VERSION "0.6.1"

NS_ :

BS_:

BU_:

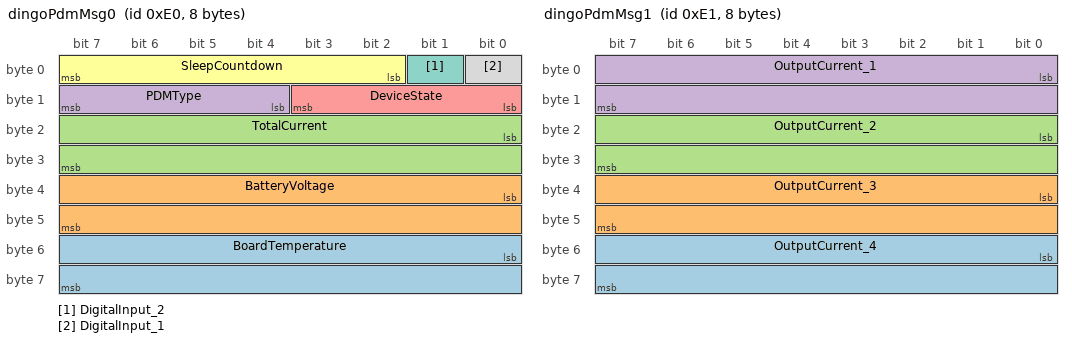
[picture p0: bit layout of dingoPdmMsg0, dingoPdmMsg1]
BO_ 224 dingoPdmMsg0: 8 Vector__XXX
 SG_ BoardTemperature : 48|16@1+ (0.1,0) [0|215] "degC" Vector__XXX
 SG_ BatteryVoltage : 32|16@1+ (0.1,0) [0|655.35] "V" Vector__XXX
 SG_ TotalCurrent : 16|16@1+ (0.1,0) [0|65535] "A" Vector__XXX
 SG_ PDMType : 12|4@1+ (1,0) [0|15] "" Vector__XXX
 SG_ DeviceState : 8|4@1+ (1,0) [0|3] "" Vector__XXX
 SG_ SleepCountdown : 2|6@1+ (1,0) [0|63] "s" Vector__XXX
 SG_ DigitalInput_2 : 1|1@1+ (1,0) [0|0] "" Vector__XXX
 SG_ DigitalInput_1 : 0|1@1+ (1,0) [0|0] "" Vector__XXX

BO_ 225 dingoPdmMsg1: 8 Vector__XXX
 SG_ OutputCurrent_4 : 48|16@1+ (0.1,0) [0|0] "A" Vector__XXX
 SG_ OutputCurrent_3 : 32|16@1+ (0.1,0) [0|0] "A" Vector__XXX
 SG_ OutputCurrent_2 : 16|16@1+ (0.1,0) [0|0] "A" Vector__XXX
 SG_ OutputCurrent_1 : 0|16@1+ (0.1,0) [0|0] "A" Vector__XXX

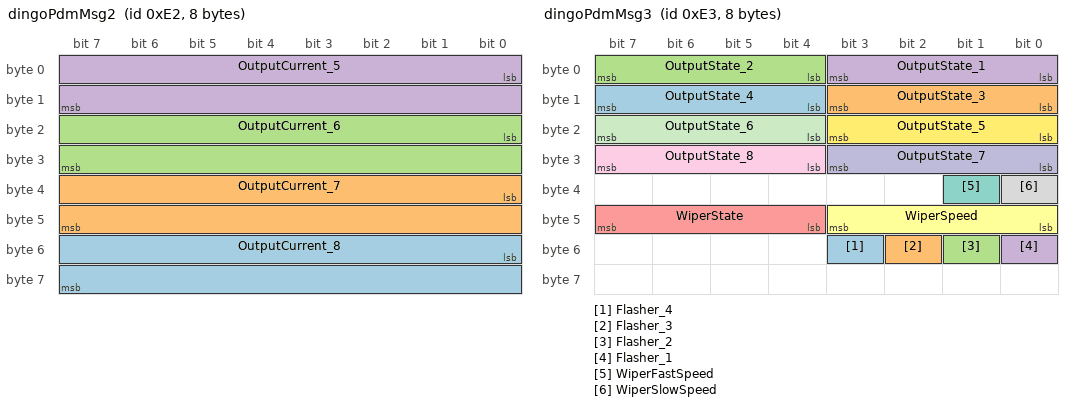
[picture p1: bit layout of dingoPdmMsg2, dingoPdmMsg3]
BO_ 226 dingoPdmMsg2: 8 Vector__XXX
 SG_ OutputCurrent_8 : 48|16@1+ (0.1,0) [0|0] "A" Vector__XXX
 SG_ OutputCurrent_7 : 32|16@1+ (0.1,0) [0|0] "A" Vector__XXX
 SG_ OutputCurrent_6 : 16|16@1+ (0.1,0) [0|0] "A" Vector__XXX
 SG_ OutputCurrent_5 : 0|16@1+ (0.1,0) [0|0] "A" Vector__XXX

BO_ 227 dingoPdmMsg3: 8 Vector__XXX
 SG_ Flasher_4 : 51|1@1+ (1,0) [0|0] "" Vector__XXX
 SG_ Flasher_3 : 50|1@1+ (1,0) [0|0] "" Vector__XXX
 SG_ Flasher_2 : 49|1@1+ (1,0) [0|0] "" Vector__XXX
 SG_ Flasher_1 : 48|1@1+ (1,0) [0|0] "" Vector__XXX
 SG_ WiperState : 44|4@1+ (1,0) [0|7] "" Vector__XXX
 SG_ WiperSpeed : 40|4@1+ (1,0) [0|8] "" Vector__XXX
 SG_ WiperFastSpeed : 33|1@1+ (1,0) [0|1] "" Vector__XXX
 SG_ WiperSlowSpeed : 32|1@1+ (1,0) [0|1] "" Vector__XXX
 SG_ OutputState_8 : 28|4@1+ (1,0) [0|0] "" Vector__XXX
 SG_ OutputState_7 : 24|4@1+ (1,0) [0|0] "" Vector__XXX
 SG_ OutputState_6 : 20|4@1+ (1,0) [0|0] "" Vector__XXX
 SG_ OutputState_5 : 16|4@1+ (1,0) [0|0] "" Vector__XXX
 SG_ OutputState_4 : 12|4@1+ (1,0) [0|0] "" Vector__XXX
 SG_ OutputState_3 : 8|4@1+ (1,0) [0|0] "" Vector__XXX
 SG_ OutputState_2 : 4|4@1+ (1,0) [0|0] "" Vector__XXX
 SG_ OutputState_1 : 0|4@1+ (1,0) [0|0] "" Vector__XXX

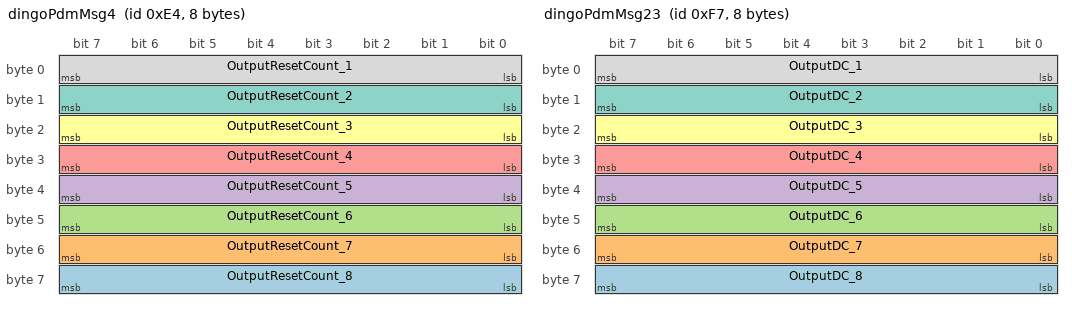
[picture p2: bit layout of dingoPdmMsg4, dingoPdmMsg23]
BO_ 228 dingoPdmMsg4: 8 Vector__XXX
 SG_ OutputResetCount_8 : 56|8@1+ (1,0) [0|0] "" Vector__XXX
 SG_ OutputResetCount_7 : 48|8@1+ (1,0) [0|0] "" Vector__XXX
 SG_ OutputResetCount_6 : 40|8@1+ (1,0) [0|0] "" Vector__XXX
 SG_ OutputResetCount_5 : 32|8@1+ (1,0) [0|0] "" Vector__XXX
 SG_ OutputResetCount_4 : 24|8@1+ (1,0) [0|0] "" Vector__XXX
 SG_ OutputResetCount_3 : 16|8@1+ (1,0) [0|0] "" Vector__XXX
 SG_ OutputResetCount_2 : 8|8@1+ (1,0) [0|0] "" Vector__XXX
 SG_ OutputResetCount_1 : 0|8@1+ (1,0) [0|0] "" Vector__XXX

BO_ 229 dingoPdmMsg5: 8 Vector__XXX
 SG_ VirtualInput_16 : 47|1@1+ (1,0) [0|0] "" Vector__XXX
 SG_ VirtualInput_15 : 46|1@1+ (1,0) [0|0] "" Vector__XXX
 SG_ VirtualInput_14 : 45|1@1+ (1,0) [0|0] "" Vector__XXX
 SG_ VirtualInput_13 : 44|1@1+ (1,0) [0|0] "" Vector__XXX
 SG_ VirtualInput_12 : 43|1@1+ (1,0) [0|0] "" Vector__XXX
 SG_ VirtualInput_11 : 42|1@1+ (1,0) [0|0] "" Vector__XXX
 SG_ VirtualInput_10 : 41|1@1+ (1,0) [0|0] "" Vector__XXX
 SG_ VirtualInput_9 : 40|1@1+ (1,0) [0|0] "" Vector__XXX
 SG_ VirtualInput_8 : 39|1@1+ (1,0) [0|0] "" Vector__XXX
 SG_ VirtualInput_7 : 38|1@1+ (1,0) [0|0] "" Vector__XXX
 SG_ VirtualInput_6 : 37|1@1+ (1,0) [0|0] "" Vector__XXX
 SG_ VirtualInput_5 : 36|1@1+ (1,0) [0|0] "" Vector__XXX
 SG_ VirtualInput_4 : 35|1@1+ (1,0) [0|0] "" Vector__XXX
 SG_ VirtualInput_3 : 34|1@1+ (1,0) [0|0] "" Vector__XXX
 SG_ VirtualInput_2 : 33|1@1+ (1,0) [0|0] "" Vector__XXX
 SG_ VirtualInput_1 : 32|1@1+ (1,0) [0|0] "" Vector__XXX
 SG_ CANInput_32 : 31|1@1+ (1,0) [0|0] "" Vector__XXX
 SG_ CANInput_31 : 30|1@1+ (1,0) [0|0] "" Vector__XXX
 SG_ CANInput_30 : 29|1@1+ (1,0) [0|0] "" Vector__XXX
 SG_ CANInput_29 : 28|1@1+ (1,0) [0|0] "" Vector__XXX
 SG_ CANInput_28 : 27|1@1+ (1,0) [0|0] "" Vector__XXX
 SG_ CANInput_27 : 26|1@1+ (1,0) [0|0] "" Vector__XXX
 SG_ CANInput_26 : 25|1@1+ (1,0) [0|0] "" Vector__XXX
 SG_ CANInput_25 : 24|1@1+ (1,0) [0|0] "" Vector__XXX
 SG_ CANInput_24 : 23|1@1+ (1,0) [0|0] "" Vector__XXX
 SG_ CANInput_23 : 22|1@1+ (1,0) [0|0] "" Vector__XXX
 SG_ CANInput_22 : 21|1@1+ (1,0) [0|0] "" Vector__XXX
 SG_ CANInput_21 : 20|1@1+ (1,0) [0|0] "" Vector__XXX
 SG_ CANInput_20 : 19|1@1+ (1,0) [0|0] "" Vector__XXX
 SG_ CANInput_19 : 18|1@1+ (1,0) [0|0] "" Vector__XXX
 SG_ CANInput_18 : 17|1@1+ (1,0) [0|0] "" Vector__XXX
 SG_ CANInput_17 : 16|1@1+ (1,0) [0|0] "" Vector__XXX
 SG_ CANInput_16 : 15|1@1+ (1,0) [0|0] "" Vector__XXX
 SG_ CANInput_15 : 14|1@1+ (1,0) [0|0] "" Vector__XXX
 SG_ CANInput_14 : 13|1@1+ (1,0) [0|0] "" Vector__XXX
 SG_ CANInput_13 : 12|1@1+ (1,0) [0|0] "" Vector__XXX
 SG_ CANInput_12 : 11|1@1+ (1,0) [0|0] "" Vector__XXX
 SG_ CANInput_11 : 10|1@1+ (1,0) [0|0] "" Vector__XXX
 SG_ CANInput_10 : 9|1@1+ (1,0) [0|0] "" Vector__XXX
 SG_ CANInput_9 : 8|1@1+ (1,0) [0|0] "" Vector__XXX
 SG_ CANInput_8 : 7|1@1+ (1,0) [0|0] "" Vector__XXX
 SG_ CANInput_7 : 6|1@1+ (1,0) [0|0] "" Vector__XXX
 SG_ CANInput_6 : 5|1@1+ (1,0) [0|0] "" Vector__XXX
 SG_ CANInput_5 : 4|1@1+ (1,0) [0|0] "" Vector__XXX
 SG_ CANInput_4 : 3|1@1+ (1,0) [0|0] "" Vector__XXX
 SG_ CANInput_3 : 2|1@1+ (1,0) [0|0] "" Vector__XXX
 SG_ CANInput_2 : 1|1@1+ (1,0) [0|0] "" Vector__XXX
 SG_ CANInput_1 : 0|1@1+ (1,0) [0|0] "" Vector__XXX

BO_ 230 dingoPdmMsg6: 8 Vector__XXX
 SG_ ConditionResult_32 : 63|1@1+ (1,0) [0|0] "" Vector__XXX
 SG_ ConditionResult_31 : 62|1@1+ (1,0) [0|0] "" Vector__XXX
 SG_ ConditionResult_30 : 61|1@1+ (1,0) [0|0] "" Vector__XXX
 SG_ ConditionResult_29 : 60|1@1+ (1,0) [0|0] "" Vector__XXX
 SG_ ConditionResult_28 : 59|1@1+ (1,0) [0|0] "" Vector__XXX
 SG_ ConditionResult_27 : 58|1@1+ (1,0) [0|0] "" Vector__XXX
 SG_ ConditionResult_26 : 57|1@1+ (1,0) [0|0] "" Vector__XXX
 SG_ ConditionResult_25 : 56|1@1+ (1,0) [0|0] "" Vector__XXX
 SG_ ConditionResult_24 : 55|1@1+ (1,0) [0|0] "" Vector__XXX
 SG_ ConditionResult_23 : 54|1@1+ (1,0) [0|0] "" Vector__XXX
 SG_ ConditionResult_22 : 53|1@1+ (1,0) [0|0] "" Vector__XXX
 SG_ ConditionResult_21 : 52|1@1+ (1,0) [0|0] "" Vector__XXX
 SG_ ConditionResult_20 : 51|1@1+ (1,0) [0|0] "" Vector__XXX
 SG_ ConditionResult_19 : 50|1@1+ (1,0) [0|0] "" Vector__XXX
 SG_ ConditionResult_18 : 49|1@1+ (1,0) [0|0] "" Vector__XXX
 SG_ ConditionResult_17 : 48|1@1+ (1,0) [0|0] "" Vector__XXX
 SG_ ConditionResult_16 : 47|1@1+ (1,0) [0|0] "" Vector__XXX
 SG_ ConditionResult_15 : 46|1@1+ (1,0) [0|0] "" Vector__XXX
 SG_ ConditionResult_14 : 45|1@1+ (1,0) [0|0] "" Vector__XXX
 SG_ ConditionResult_13 : 44|1@1+ (1,0) [0|0] "" Vector__XXX
 SG_ ConditionResult_12 : 43|1@1+ (1,0) [0|0] "" Vector__XXX
 SG_ ConditionResult_11 : 42|1@1+ (1,0) [0|0] "" Vector__XXX
 SG_ ConditionResult_10 : 41|1@1+ (1,0) [0|0] "" Vector__XXX
 SG_ ConditionResult_9 : 40|1@1+ (1,0) [0|0] "" Vector__XXX
 SG_ ConditionResult_8 : 39|1@1+ (1,0) [0|0] "" Vector__XXX
 SG_ ConditionResult_7 : 38|1@1+ (1,0) [0|0] "" Vector__XXX
 SG_ ConditionResult_6 : 37|1@1+ (1,0) [0|0] "" Vector__XXX
 SG_ ConditionResult_5 : 36|1@1+ (1,0) [0|0] "" Vector__XXX
 SG_ ConditionResult_4 : 35|1@1+ (1,0) [0|0] "" Vector__XXX
 SG_ ConditionResult_3 : 34|1@1+ (1,0) [0|0] "" Vector__XXX
 SG_ ConditionResult_2 : 33|1@1+ (1,0) [0|0] "" Vector__XXX
 SG_ ConditionResult_1 : 32|1@1+ (1,0) [0|0] "" Vector__XXX
 SG_ CounterValue_4 : 24|8@1+ (1,0) [0|0] "" Vector__XXX
 SG_ CounterValue_3 : 16|8@1+ (1,0) [0|0] "" Vector__XXX
 SG_ CounterValue_2 : 8|8@1+ (1,0) [0|0] "" Vector__XXX
 SG_ CounterValue_1 : 0|8@1+ (1,0) [0|0] "" Vector__XXX

BO_ 231 dingoPdmMsg7: 8 Vector__XXX
 SG_ CANInputValue_2 : 32|32@1+ (1,0) [0|0] "" Vector__XXX
 SG_ CANInputValue_1 : 0|32@1+ (1,0) [0|0] "" Vector__XXX

BO_ 232 dingoPdmMsg8: 8 Vector__XXX
 SG_ CANInputValue_4 : 32|32@1+ (1,0) [0|0] "" Vector__XXX
 SG_ CANInputValue_3 : 0|32@1+ (1,0) [0|0] "" Vector__XXX

BO_ 233 dingoPdmMsg9: 8 Vector__XXX
 SG_ CANInputValue_6 : 32|32@1+ (1,0) [0|0] "" Vector__XXX
 SG_ CANInputValue_5 : 0|32@1+ (1,0) [0|0] "" Vector__XXX

BO_ 234 dingoPdmMsg10: 8 Vector__XXX
 SG_ CANInputValue_8 : 32|32@1+ (1,0) [0|0] "" Vector__XXX
 SG_ CANInputValue_7 : 0|32@1+ (1,0) [0|0] "" Vector__XXX

BO_ 235 dingoPdmMsg11: 8 Vector__XXX
 SG_ CANInputValue_10 : 32|32@1+ (1,0) [0|0] "" Vector__XXX
 SG_ CANInputValue_9 : 0|32@1+ (1,0) [0|0] "" Vector__XXX

BO_ 236 dingoPdmMsg12: 8 Vector__XXX
 SG_ CANInputValue_12 : 32|32@1+ (1,0) [0|0] "" Vector__XXX
 SG_ CANInputValue_11 : 0|32@1+ (1,0) [0|0] "" Vector__XXX

BO_ 237 dingoPdmMsg13: 8 Vector__XXX
 SG_ CANInputValue_14 : 32|32@1+ (1,0) [0|0] "" Vector__XXX
 SG_ CANInputValue_13 : 0|32@1+ (1,0) [0|0] "" Vector__XXX

BO_ 238 dingoPdmMsg14: 8 Vector__XXX
 SG_ CANInputValue_16 : 32|32@1+ (1,0) [0|0] "" Vector__XXX
 SG_ CANInputValue_15 : 0|32@1+ (1,0) [0|0] "" Vector__XXX

BO_ 239 dingoPdmMsg15: 8 Vector__XXX
 SG_ CANInputValue_18 : 32|32@1+ (1,0) [0|0] "" Vector__XXX
 SG_ CANInputValue_17 : 0|32@1+ (1,0) [0|0] "" Vector__XXX

BO_ 240 dingoPdmMsg16: 8 Vector__XXX
 SG_ CANInputValue_20 : 32|32@1+ (1,0) [0|0] "" Vector__XXX
 SG_ CANInputValue_19 : 0|32@1+ (1,0) [0|0] "" Vector__XXX

BO_ 241 dingoPdmMsg17: 8 Vector__XXX
 SG_ CANInputValue_22 : 32|32@1+ (1,0) [0|0] "" Vector__XXX
 SG_ CANInputValue_21 : 0|32@1+ (1,0) [0|0] "" Vector__XXX

BO_ 242 dingoPdmMsg18: 8 Vector__XXX
 SG_ CANInputValue_24 : 32|32@1+ (1,0) [0|0] "" Vector__XXX
 SG_ CANInputValue_23 : 0|32@1+ (1,0) [0|0] "" Vector__XXX

BO_ 243 dingoPdmMsg19: 8 Vector__XXX
 SG_ CANInputValue_26 : 32|32@1+ (1,0) [0|0] "" Vector__XXX
 SG_ CANInputValue_25 : 0|32@1+ (1,0) [0|0] "" Vector__XXX

BO_ 244 dingoPdmMsg20: 8 Vector__XXX
 SG_ CANInputValue_28 : 32|32@1+ (1,0) [0|0] "" Vector__XXX
 SG_ CANInputValue_27 : 0|32@1+ (1,0) [0|0] "" Vector__XXX

BO_ 245 dingoPdmMsg21: 8 Vector__XXX
 SG_ CANInputValue_30 : 32|32@1+ (1,0) [0|0] "" Vector__XXX
 SG_ CANInputValue_29 : 0|32@1+ (1,0) [0|0] "" Vector__XXX

BO_ 246 dingoPdmMsg22: 8 Vector__XXX
 SG_ CANInputValue_32 : 32|32@1+ (1,0) [0|0] "" Vector__XXX
 SG_ CANInputValue_31 : 0|32@1+ (1,0) [0|0] "" Vector__XXX

BO_ 247 dingoPdmMsg23: 8 Vector__XXX
 SG_ OutputDC_8 : 56|8@1+ (1,0) [0|0] "%" Vector__XXX
 SG_ OutputDC_7 : 48|8@1+ (1,0) [0|0] "%" Vector__XXX
 SG_ OutputDC_6 : 40|8@1+ (1,0) [0|0] "%" Vector__XXX
 SG_ OutputDC_5 : 32|8@1+ (1,0) [0|0] "%" Vector__XXX
 SG_ OutputDC_4 : 24|8@1+ (1,0) [0|0] "%" Vector__XXX
 SG_ OutputDC_3 : 16|8@1+ (1,0) [0|0] "%" Vector__XXX
 SG_ OutputDC_2 : 8|8@1+ (1,0) [0|0] "%" Vector__XXX
 SG_ OutputDC_1 : 0|8@1+ (1,0) [0|0] "%" Vector__XXX

BO_ 248 dingoPdmMsg24: 8 Vector__XXX
 SG_ Keypad1Button_20 : 43|1@1+ (1,0) [0|0] "" Vector__XXX
 SG_ Keypad1Button_19 : 42|1@1+ (1,0) [0|0] "" Vector__XXX
 SG_ Keypad1Button_18 : 41|1@1+ (1,0) [0|0] "" Vector__XXX
 SG_ Keypad1Button_17 : 40|1@1+ (1,0) [0|0] "" Vector__XXX
 SG_ Keypad1Button_16 : 39|1@1+ (1,0) [0|0] "" Vector__XXX
 SG_ Keypad1Button_15 : 38|1@1+ (1,0) [0|0] "" Vector__XXX
 SG_ Keypad1Button_14 : 37|1@1+ (1,0) [0|0] "" Vector__XXX
 SG_ Keypad1Button_13 : 36|1@1+ (1,0) [0|0] "" Vector__XXX
 SG_ Keypad1Button_12 : 35|1@1+ (1,0) [0|0] "" Vector__XXX
 SG_ Keypad1Button_11 : 34|1@1+ (1,0) [0|0] "" Vector__XXX
 SG_ Keypad1Button_10 : 33|1@1+ (1,0) [0|0] "" Vector__XXX
 SG_ Keypad1Button_9 : 32|1@1+ (1,0) [0|0] "" Vector__XXX
 SG_ Keypad1Button_8 : 31|1@1+ (1,0) [0|0] "" Vector__XXX
 SG_ Keypad1Button_7 : 30|1@1+ (1,0) [0|0] "" Vector__XXX
 SG_ Keypad1Button_6 : 29|1@1+ (1,0) [0|0] "" Vector__XXX
 SG_ Keypad1Button_5 : 28|1@1+ (1,0) [0|0] "" Vector__XXX
 SG_ Keypad1Button_4 : 27|1@1+ (1,0) [0|0] "" Vector__XXX
 SG_ Keypad1Button_3 : 26|1@1+ (1,0) [0|0] "" Vector__XXX
 SG_ Keypad1Button_2 : 25|1@1+ (1,0) [0|0] "" Vector__XXX
 SG_ Keypad1Button_1 : 24|1@1+ (1,0) [0|0] "" Vector__XXX
 SG_ Keypad0Button_20 : 19|1@1+ (1,0) [0|0] "" Vector__XXX
 SG_ Keypad0Button_19 : 18|1@1+ (1,0) [0|0] "" Vector__XXX
 SG_ Keypad0Button_18 : 17|1@1+ (1,0) [0|0] "" Vector__XXX
 SG_ Keypad0Button_17 : 16|1@1+ (1,0) [0|0] "" Vector__XXX
 SG_ Keypad0Button_16 : 15|1@1+ (1,0) [0|0] "" Vector__XXX
 SG_ Keypad0Button_15 : 14|1@1+ (1,0) [0|0] "" Vector__XXX
 SG_ Keypad0Button_14 : 13|1@1+ (1,0) [0|0] "" Vector__XXX
 SG_ Keypad0Button_13 : 12|1@1+ (1,0) [0|0] "" Vector__XXX
 SG_ Keypad0Button_12 : 11|1@1+ (1,0) [0|0] "" Vector__XXX
 SG_ Keypad0Button_11 : 10|1@1+ (1,0) [0|0] "" Vector__XXX
 SG_ Keypad0Button_10 : 9|1@1+ (1,0) [0|0] "" Vector__XXX
 SG_ Keypad0Button_9 : 8|1@1+ (1,0) [0|0] "" Vector__XXX
 SG_ Keypad0Button_8 : 7|1@1+ (1,0) [0|0] "" Vector__XXX
 SG_ Keypad0Button_7 : 6|1@1+ (1,0) [0|0] "" Vector__XXX
 SG_ Keypad0Button_6 : 5|1@1+ (1,0) [0|0] "" Vector__XXX
 SG_ Keypad0Button_5 : 4|1@1+ (1,0) [0|0] "" Vector__XXX
 SG_ Keypad0Button_4 : 3|1@1+ (1,0) [0|0] "" Vector__XXX
 SG_ Keypad0Button_3 : 2|1@1+ (1,0) [0|0] "" Vector__XXX
 SG_ Keypad0Button_2 : 1|1@1+ (1,0) [0|0] "" Vector__XXX
 SG_ Keypad0Button_1 : 0|1@1+ (1,0) [0|0] "" Vector__XXX

BO_ 249 dingoPdmMsg25: 8 Vector__XXX
 SG_ Keypad0Dial_2 : 16|16@1+ (1,0) [0|0] "" Vector__XXX
 SG_ Keypad0Dial_1 : 0|16@1+ (1,0) [0|0] "" Vector__XXX

BO_ 250 dingoPdmMsg26: 8 Vector__XXX
 SG_ Keypad1Dial_2 : 16|16@1+ (1,0) [0|0] "" Vector__XXX
 SG_ Keypad1Dial_1 : 0|16@1+ (1,0) [0|0] "" Vector__XXX

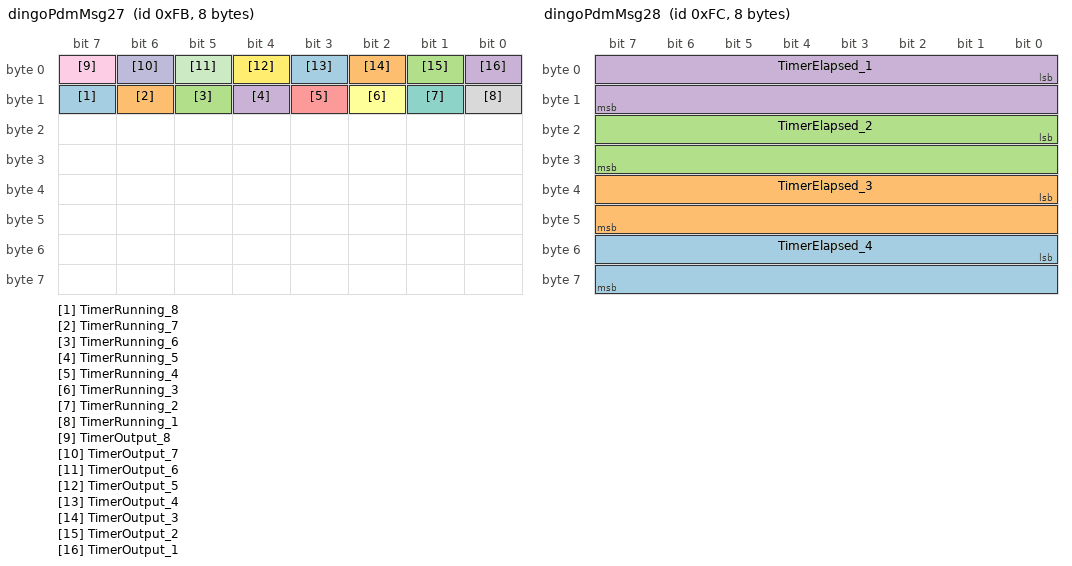
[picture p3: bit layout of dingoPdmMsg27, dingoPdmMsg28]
BO_ 251 dingoPdmMsg27: 8 Vector__XXX
 SG_ TimerRunning_8 : 15|1@1+ (1,0) [0|0] "" Vector__XXX
 SG_ TimerRunning_7 : 14|1@1+ (1,0) [0|0] "" Vector__XXX
 SG_ TimerRunning_6 : 13|1@1+ (1,0) [0|0] "" Vector__XXX
 SG_ TimerRunning_5 : 12|1@1+ (1,0) [0|0] "" Vector__XXX
 SG_ TimerRunning_4 : 11|1@1+ (1,0) [0|0] "" Vector__XXX
 SG_ TimerRunning_3 : 10|1@1+ (1,0) [0|0] "" Vector__XXX
 SG_ TimerRunning_2 : 9|1@1+ (1,0) [0|0] "" Vector__XXX
 SG_ TimerRunning_1 : 8|1@1+ (1,0) [0|0] "" Vector__XXX
 SG_ TimerOutput_8 : 7|1@1+ (1,0) [0|0] "" Vector__XXX
 SG_ TimerOutput_7 : 6|1@1+ (1,0) [0|0] "" Vector__XXX
 SG_ TimerOutput_6 : 5|1@1+ (1,0) [0|0] "" Vector__XXX
 SG_ TimerOutput_5 : 4|1@1+ (1,0) [0|0] "" Vector__XXX
 SG_ TimerOutput_4 : 3|1@1+ (1,0) [0|0] "" Vector__XXX
 SG_ TimerOutput_3 : 2|1@1+ (1,0) [0|0] "" Vector__XXX
 SG_ TimerOutput_2 : 1|1@1+ (1,0) [0|0] "" Vector__XXX
 SG_ TimerOutput_1 : 0|1@1+ (1,0) [0|0] "" Vector__XXX

BO_ 252 dingoPdmMsg28: 8 Vector__XXX
 SG_ TimerElapsed_4 : 48|16@1+ (0.01,0) [0|655.35] "s" Vector__XXX
 SG_ TimerElapsed_3 : 32|16@1+ (0.01,0) [0|655.35] "s" Vector__XXX
 SG_ TimerElapsed_2 : 16|16@1+ (0.01,0) [0|655.35] "s" Vector__XXX
 SG_ TimerElapsed_1 : 0|16@1+ (0.01,0) [0|655.35] "s" Vector__XXX

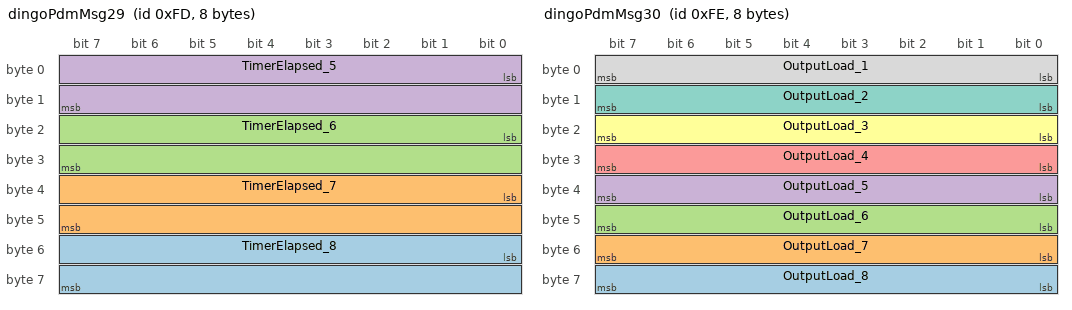
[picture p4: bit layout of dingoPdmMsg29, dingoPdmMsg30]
BO_ 253 dingoPdmMsg29: 8 Vector__XXX
 SG_ TimerElapsed_8 : 48|16@1+ (0.01,0) [0|655.35] "s" Vector__XXX
 SG_ TimerElapsed_7 : 32|16@1+ (0.01,0) [0|655.35] "s" Vector__XXX
 SG_ TimerElapsed_6 : 16|16@1+ (0.01,0) [0|655.35] "s" Vector__XXX
 SG_ TimerElapsed_5 : 0|16@1+ (0.01,0) [0|655.35] "s" Vector__XXX

BO_ 254 dingoPdmMsg30: 8 Vector__XXX
 SG_ OutputLoad_8 : 56|8@1+ (1,0) [0|255] "%" Vector__XXX
 SG_ OutputLoad_7 : 48|8@1+ (1,0) [0|255] "%" Vector__XXX
 SG_ OutputLoad_6 : 40|8@1+ (1,0) [0|255] "%" Vector__XXX
 SG_ OutputLoad_5 : 32|8@1+ (1,0) [0|255] "%" Vector__XXX
 SG_ OutputLoad_4 : 24|8@1+ (1,0) [0|255] "%" Vector__XXX
 SG_ OutputLoad_3 : 16|8@1+ (1,0) [0|255] "%" Vector__XXX
 SG_ OutputLoad_2 : 8|8@1+ (1,0) [0|255] "%" Vector__XXX
 SG_ OutputLoad_1 : 0|8@1+ (1,0) [0|255] "%" Vector__XXX

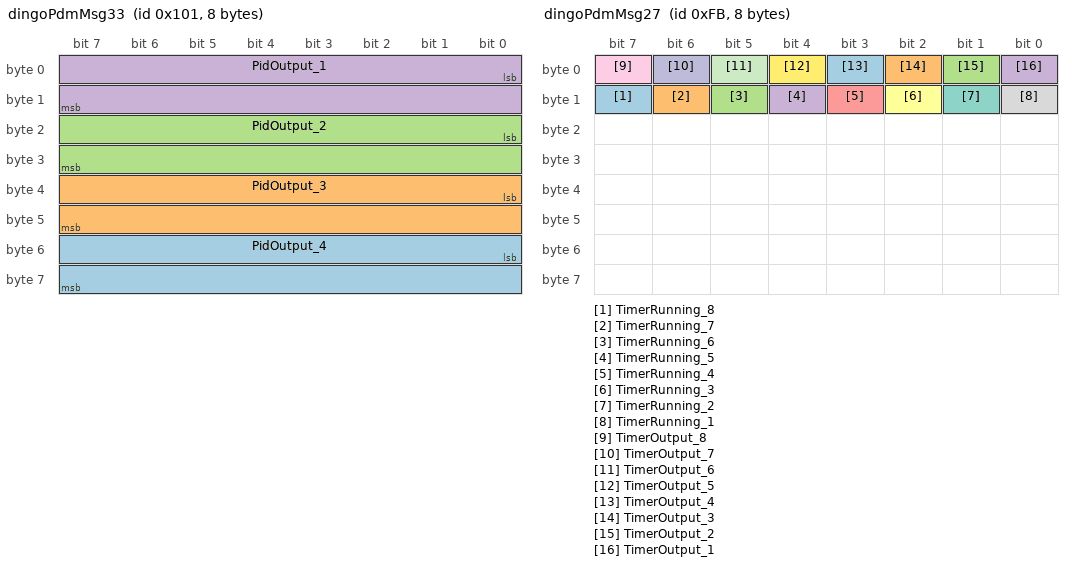
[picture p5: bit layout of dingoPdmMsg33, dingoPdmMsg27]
BO_ 257 dingoPdmMsg33: 8 Vector__XXX
 SG_ PidOutput_4 : 48|16@1- (0.1,0) [0|0] "" Vector__XXX
 SG_ PidOutput_3 : 32|16@1- (0.1,0) [0|0] "" Vector__XXX
 SG_ PidOutput_2 : 16|16@1- (0.1,0) [0|0] "" Vector__XXX
 SG_ PidOutput_1 : 0|16@1- (0.1,0) [0|0] "" Vector__XXX

BO_ 251 dingoPdmMsg27: 8 Vector__XXX
 SG_ TimerRunning_8 : 15|1@1+ (1,0) [0|0] "" Vector__XXX
 SG_ TimerRunning_7 : 14|1@1+ (1,0) [0|0] "" Vector__XXX
 SG_ TimerRunning_6 : 13|1@1+ (1,0) [0|0] "" Vector__XXX
 SG_ TimerRunning_5 : 12|1@1+ (1,0) [0|0] "" Vector__XXX
 SG_ TimerRunning_4 : 11|1@1+ (1,0) [0|0] "" Vector__XXX
 SG_ TimerRunning_3 : 10|1@1+ (1,0) [0|0] "" Vector__XXX
 SG_ TimerRunning_2 : 9|1@1+ (1,0) [0|0] "" Vector__XXX
 SG_ TimerRunning_1 : 8|1@1+ (1,0) [0|0] "" Vector__XXX
 SG_ TimerOutput_8 : 7|1@1+ (1,0) [0|0] "" Vector__XXX
 SG_ TimerOutput_7 : 6|1@1+ (1,0) [0|0] "" Vector__XXX
 SG_ TimerOutput_6 : 5|1@1+ (1,0) [0|0] "" Vector__XXX
 SG_ TimerOutput_5 : 4|1@1+ (1,0) [0|0] "" Vector__XXX
 SG_ TimerOutput_4 : 3|1@1+ (1,0) [0|0] "" Vector__XXX
 SG_ TimerOutput_3 : 2|1@1+ (1,0) [0|0] "" Vector__XXX
 SG_ TimerOutput_2 : 1|1@1+ (1,0) [0|0] "" Vector__XXX
 SG_ TimerOutput_1 : 0|1@1+ (1,0) [0|0] "" Vector__XXX

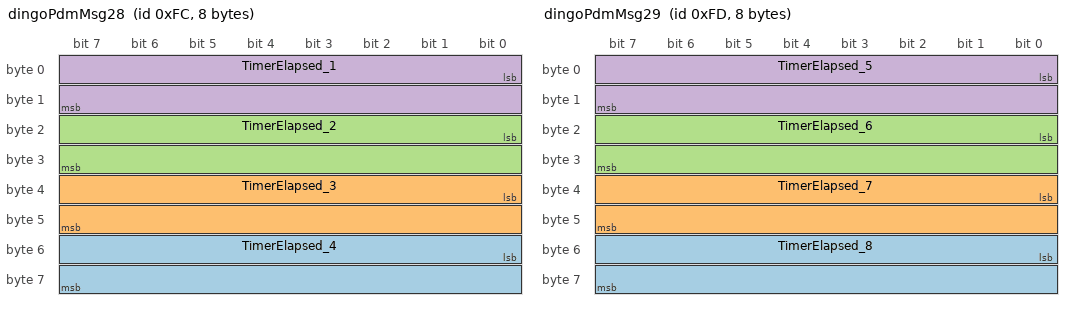
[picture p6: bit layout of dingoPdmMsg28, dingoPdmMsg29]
BO_ 252 dingoPdmMsg28: 8 Vector__XXX
 SG_ TimerElapsed_4 : 48|16@1+ (0.01,0) [0|655.35] "s" Vector__XXX
 SG_ TimerElapsed_3 : 32|16@1+ (0.01,0) [0|655.35] "s" Vector__XXX
 SG_ TimerElapsed_2 : 16|16@1+ (0.01,0) [0|655.35] "s" Vector__XXX
 SG_ TimerElapsed_1 : 0|16@1+ (0.01,0) [0|655.35] "s" Vector__XXX

BO_ 253 dingoPdmMsg29: 8 Vector__XXX
 SG_ TimerElapsed_8 : 48|16@1+ (0.01,0) [0|655.35] "s" Vector__XXX
 SG_ TimerElapsed_7 : 32|16@1+ (0.01,0) [0|655.35] "s" Vector__XXX
 SG_ TimerElapsed_6 : 16|16@1+ (0.01,0) [0|655.35] "s" Vector__XXX
 SG_ TimerElapsed_5 : 0|16@1+ (0.01,0) [0|655.35] "s" Vector__XXX

BO_ 255 dingoPdmMsg31: 8 Vector__XXX
 SG_ TableValue_2 : 32|32@1- (1,0) [0|0] "" Vector__XXX
 SG_ TableValue_1 : 0|32@1- (1,0) [0|0] "" Vector__XXX

BO_ 256 dingoPdmMsg32: 8 Vector__XXX
 SG_ TableValue_4 : 32|32@1- (1,0) [0|0] "" Vector__XXX
 SG_ TableValue_3 : 0|32@1- (1,0) [0|0] "" Vector__XXX

BO_ 258 dingoPdmMsg34: 8 Vector__XXX
 SG_ WakeFromSleep : 63|1@1+ (1,0) [0|1] "" Vector__XXX
 SG_ WakeOther : 59|1@1+ (1,0) [0|1] "" Vector__XXX
 SG_ WakeUsb : 58|1@1+ (1,0) [0|1] "" Vector__XXX
 SG_ WakeDigIn : 57|1@1+ (1,0) [0|1] "" Vector__XXX
 SG_ WakeCan : 56|1@1+ (1,0) [0|1] "" Vector__XXX
 SG_ IgnDashShutdown : 54|1@1+ (1,0) [0|1] "" Vector__XXX
 SG_ IgnReady : 53|1@1+ (1,0) [0|1] "" Vector__XXX
 SG_ IgnRunning : 52|1@1+ (1,0) [0|1] "" Vector__XXX
 SG_ IgnStarter : 51|1@1+ (1,0) [0|1] "" Vector__XXX
 SG_ IgnDash : 50|1@1+ (1,0) [0|1] "" Vector__XXX
 SG_ IgnAccessory : 49|1@1+ (1,0) [0|1] "" Vector__XXX
 SG_ IgnIgnition : 48|1@1+ (1,0) [0|1] "" Vector__XXX
 SG_ IgnSleepCountdown : 32|16@1+ (1,0) [0|3600] "" Vector__XXX
 SG_ IgnLink : 24|8@1+ (1,0) [0|3] "" Vector__XXX
 SG_ IgnSleepStatus : 16|8@1+ (1,0) [0|7] "" Vector__XXX
 SG_ IgnDashState : 8|8@1+ (1,0) [0|4] "" Vector__XXX
 SG_ IgnRole : 4|4@1+ (1,0) [0|2] "" Vector__XXX
 SG_ IgnState : 0|4@1+ (1,0) [0|3] "" Vector__XXX

CM_ SG_ 224 SleepCountdown "Seconds until auto sleep, 63 = not counting down";

VAL_ 224 PDMType 0 "dingoPDM" 1 "dingoPDM-Max" ;
VAL_ 224 DeviceState 0 "Run" 1 "Sleep" 2 "Overtemp" 3 "Error" ;
VAL_ 227 WiperState 0 "Park" 1 "Parking" 2 "Slow" 3 "Fast" 4 "Intermit Pause" 5 "Intermit On" 6 "Wash" 7 "Swipe" ;
VAL_ 227 WiperSpeed 0 "Park" 1 "Slow" 2 "Fast" 3 "Intermit Speed 1" 4 "Intermit Speed 2" 5 "Intermit Speed 3" 6 "Intermit Speed 4" 7 "Intermit Speed 5" 8 "Intermit Speed 6" ;
VAL_ 227 OutputState_8 0 "Off" 1 "On" 2 "Overcurrent" 3 "Fault" 4 "Warning" 5 "OpenLoad" 6 "Undercurrent" ;
VAL_ 227 OutputState_7 0 "Off" 1 "On" 2 "Overcurrent" 3 "Fault" 4 "Warning" 5 "OpenLoad" 6 "Undercurrent" ;
VAL_ 227 OutputState_6 0 "Off" 1 "On" 2 "Overcurrent" 3 "Fault" 4 "Warning" 5 "OpenLoad" 6 "Undercurrent" ;
VAL_ 227 OutputState_5 0 "Off" 1 "On" 2 "Overcurrent" 3 "Fault" 4 "Warning" 5 "OpenLoad" 6 "Undercurrent" ;
VAL_ 227 OutputState_4 0 "Off" 1 "On" 2 "Overcurrent" 3 "Fault" 4 "Warning" 5 "OpenLoad" 6 "Undercurrent" ;
VAL_ 227 OutputState_3 0 "Off" 1 "On" 2 "Overcurrent" 3 "Fault" 4 "Warning" 5 "OpenLoad" 6 "Undercurrent" ;
VAL_ 227 OutputState_2 0 "Off" 1 "On" 2 "Overcurrent" 3 "Fault" 4 "Warning" 5 "OpenLoad" 6 "Undercurrent" ;
VAL_ 227 OutputState_1 0 "Off" 1 "On" 2 "Overcurrent" 3 "Fault" 4 "Warning" 5 "OpenLoad" 6 "Undercurrent" ;
VAL_ 258 IgnLink 0 "NotFollower" 1 "Ok" 2 "Lost" 3 "SyncIdInvalid" ;
VAL_ 258 IgnSleepStatus 0 "Disabled" 1 "Awake" 2 "Counting" 3 "Following" 4 "WaitingDash" 5 "Held" 6 "Quiet" 7 "Sleep" ;
VAL_ 258 IgnDashState 0 "Off" 1 "On" 2 "Grace" 3 "Halting" 4 "Restart" ;
VAL_ 258 IgnRole 0 "Main" 1 "Follower" 2 "Standalone" ;
VAL_ 258 IgnState 0 "Off" 1 "On" 2 "Cranking" 3 "Running" ;
SIG_VALTYPE_ 255 TableValue_1 : 1;
SIG_VALTYPE_ 255 TableValue_2 : 1;
SIG_VALTYPE_ 256 TableValue_3 : 1;
SIG_VALTYPE_ 256 TableValue_4 : 1;
